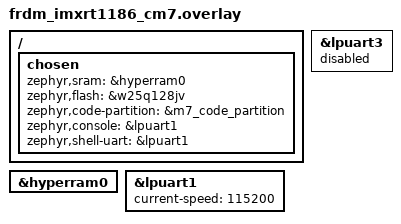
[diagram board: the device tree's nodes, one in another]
/*
 * tools/app/zephyr/v4.4.2/boards/frdm_imxrt1186_cm7.overlay -- the M7
 * application of decision 0023, over Zephyr's frdm_imxrt1186/mimxrt1186/cm7,
 * with frdm_imxrt1186_nor.overlay beside it:
 *
 *   - its code runs in place from the NOR's m7_code_partition (the launcher
 *     releases it there, CONFIG_CM7_BOOT_FROM_FLASH);
 *   - its RAM is the HyperRAM, which the ROM set up from the launcher's XMCD
 *     (0x2800_0000 in the M7's view); the DTCM stays zephyr,dtcm;
 *   - its console is LPUART1, the board's enumerated VCOM (LPUART3's needs
 *     jumper J34).
 */
/ {
	chosen {
		zephyr,sram = &hyperram0;
		zephyr,flash = &w25q128jv;
		zephyr,code-partition = &m7_code_partition;
		zephyr,console = &lpuart1;
		zephyr,shell-uart = &lpuart1;
	};
};

&hyperram0 {
	status = "okay";
};

&lpuart1 {
	status = "okay";
	current-speed = <115200>;
};

&lpuart3 {
	status = "disabled";
};
